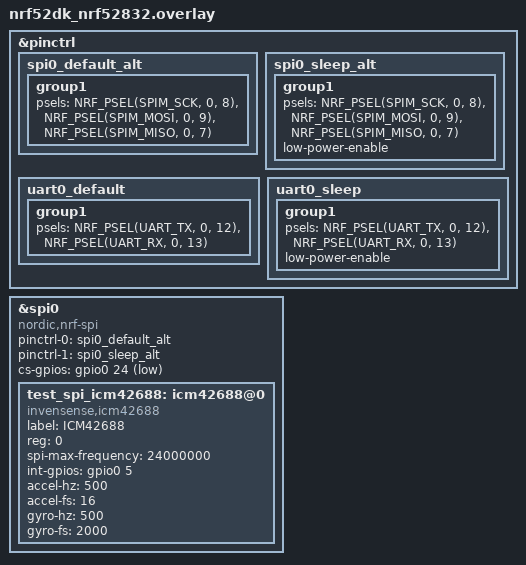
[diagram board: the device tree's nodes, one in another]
// To get started, press Ctrl+Space to bring up the completion menu and view the available nodes.

// You can also use the buttons in the sidebar to perform actions on nodes.
// Actions currently available include:

// * Enabling / disabling the node
// * Adding the bus to a bus
// * Removing the node
// * Connecting ADC channels

// For more help, browse the DeviceTree documentation at https: //docs.zephyrproject.org/latest/guides/dts/index.html
// You can also visit the nRF DeviceTree extension documentation at https: //nrfconnect.github.io/vscode-nrf-connect/devicetree/nrfdevicetree.html
&pinctrl {
    spi0_default_alt: spi0_default_alt {
        group1 {
            psels = <NRF_PSEL(SPIM_SCK, 0, 8)>,
                    <NRF_PSEL(SPIM_MOSI, 0, 9)>,
                    <NRF_PSEL(SPIM_MISO, 0, 7)>;
        };
    };

    spi0_sleep_alt: spi0_sleep_alt {
        group1 {
            psels = <NRF_PSEL(SPIM_SCK, 0, 8)>,
                    <NRF_PSEL(SPIM_MOSI, 0, 9)>,
                    <NRF_PSEL(SPIM_MISO, 0, 7)>;
            low-power-enable;
        };
    };
    uart0_default: uart0_default {
        group1 {
            psels = <NRF_PSEL(UART_TX, 0, 12)>,
                <NRF_PSEL(UART_RX, 0, 13)>;
        };
    };

    uart0_sleep: uart0_sleep {
        group1 {
            psels = <NRF_PSEL(UART_TX, 0, 12)>,
                <NRF_PSEL(UART_RX, 0, 13)>;
            low-power-enable;
        };
    };
};

&spi0 {
    compatible = "nordic,nrf-spi";
    status = "okay";
    pinctrl-0 = <&spi0_default_alt>;
    pinctrl-1 = <&spi0_sleep_alt>;
    pinctrl-names = "default", "sleep";
    cs-gpios = <&gpio0 24 GPIO_ACTIVE_LOW>;

    test_spi_icm42688: icm42688@0 {
        compatible = "invensense,icm42688";
        label = "ICM42688";
        reg = <0>;
        spi-max-frequency = <24000000>;
        int-gpios = <&gpio0 5 GPIO_ACTIVE_HIGH>;
        accel-hz = <500>;
        accel-fs = <16>;
        gyro-hz = <500>;
        gyro-fs = <2000>;
    };
};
